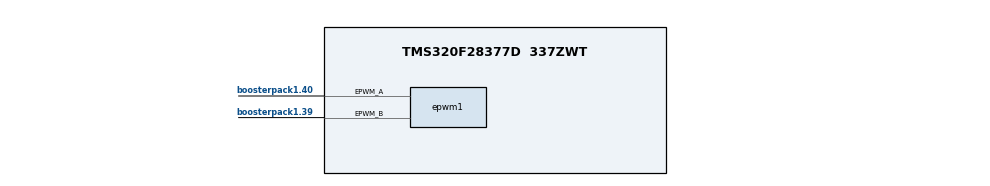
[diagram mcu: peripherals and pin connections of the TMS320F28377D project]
/**
 * These arguments were used when this file was generated. They will be automatically applied on subsequent loads
 * via the GUI or CLI. Run CLI with '--help' for additional information on how to override these arguments.
 * @cliArgs --board "/boards/LAUNCHXL_F28379D" --device "F2837xD" --part "F2837xD_337ZWT" --package "F2837xD_337ZWT" --context "CPU1" --product "C2000WARE@5.04.00.00"
 * @v2CliArgs --board "/boards/LAUNCHXL_F28379D" --device "TMS320F28377D" --package "337ZWT" --context "CPU1" --product "C2000WARE@5.04.00.00"
 * @versions {"tool":"1.23.0+4000"}
 */

/**
 * Import the modules used in this configuration.
 */
const epwm  = scripting.addModule("/driverlib/epwm.js", {}, false);
const epwm1 = epwm.addInstance();
const gpio  = scripting.addModule("/driverlib/gpio.js", {}, false);
const gpio1 = gpio.addInstance();

/**
 * Write custom configuration values to the imported modules.
 */
epwm1.$name                                                      = "Pwm_FPB";
epwm1.epwmActionQualifier_EPWM_AQ_OUTPUT_A_ON_TIMEBASE_UP_CMPA   = "EPWM_AQ_OUTPUT_HIGH";
epwm1.epwmActionQualifier_EPWM_AQ_OUTPUT_A_ON_TIMEBASE_DOWN_CMPA = "EPWM_AQ_OUTPUT_LOW";
epwm1.epwmTimebase_counterMode                                   = "EPWM_COUNTER_MODE_UP_DOWN";
epwm1.epwmTimebase_counterModeAfterSync                          = "EPWM_COUNT_MODE_UP_AFTER_SYNC";
epwm1.epwmTimebase_emulationMode                                 = "EPWM_EMULATION_FREE_RUN";
epwm1.epwmTimebase_period                                        = 2500;
epwm1.epwmCounterCompare_cmpA                                    = 1250;
epwm1.epwmTimebase_hsClockDiv                                    = "EPWM_HSCLOCK_DIVIDER_1";
epwm1.epwmActionQualifier_EPWM_AQ_OUTPUT_B_ON_TIMEBASE_UP_CMPB   = "EPWM_AQ_OUTPUT_HIGH";
epwm1.epwmActionQualifier_EPWM_AQ_OUTPUT_B_ON_TIMEBASE_DOWN_CMPB = "EPWM_AQ_OUTPUT_LOW";
epwm1.epwmCounterCompare_cmpB                                    = 1250;
epwm1.epwm.$assign                                               = "EPWM1";
epwm1.epwm.epwm_aPin.$assign                                     = "boosterpack1.40";
epwm1.epwm.epwm_bPin.$assign                                     = "boosterpack1.39";
scripting.suppress("Connected to hardware,@@@.+?@@@ is connected to EPWM1 BP on the LaunchPad F28379D\\. Consider selecting it in \'use hardware\' above\\. @@@.+?@@@", epwm1.epwm, "epwm_aPin");
scripting.suppress("Connected to hardware,@@@.+?@@@ is connected to EPWM1 BP on the LaunchPad F28379D\\. Consider selecting it in \'use hardware\' above\\. @@@.+?@@@", epwm1.epwm, "epwm_bPin");

gpio1.$name     = "Led_Blink";
gpio1.$hardware = system.deviceData.board.components.LED4;
gpio1.direction = "GPIO_DIR_MODE_OUT";

/**
 * Pinmux solution for unlocked pins/peripherals. This ensures that minor changes to the automatic solver in a future
 * version of the tool will not impact the pinmux you originally saw.  These lines can be completely deleted in order to
 * re-solve from scratch.
 */
gpio1.gpioPin.$suggestSolution = "GPIO31";
